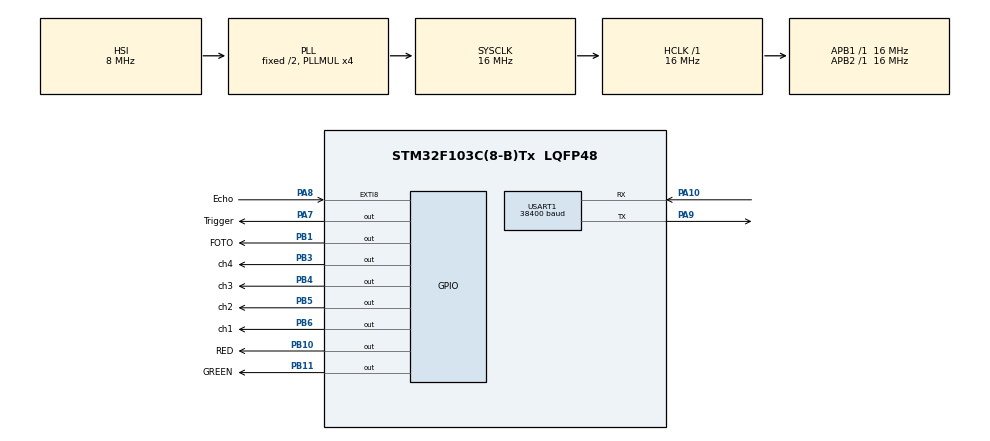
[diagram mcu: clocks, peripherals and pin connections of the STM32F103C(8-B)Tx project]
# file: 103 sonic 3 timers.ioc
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Mcu.Family=STM32F1
Mcu.Name=STM32F103C(8-B)Tx
Mcu.Package=LQFP48
NVIC.EXTI9_5_IRQn=true\:1\:0\:true\:false\:true\:true
NVIC.PriorityGroup=NVIC_PRIORITYGROUP_4
NVIC.TIM2_IRQn=true\:3\:0\:true\:false\:true\:true
NVIC.TIM3_IRQn=true\:2\:0\:true\:false\:true\:true
NVIC.TIM4_IRQn=true\:0\:0\:false\:false\:true\:true
PA10.Mode=Asynchronous
PA10.Signal=USART1_RX
PA13.Mode=Serial_Wire
PA13.Signal=SYS_JTMS-SWDIO
PA14.Mode=Serial_Wire
PA14.Signal=SYS_JTCK-SWCLK
PA7.GPIO_Label=Trigger
PA7.Signal=GPIO_Output
PA8.GPIO_Label=Echo
PA8.GPIO_ModeDefaultEXTI=GPIO_MODE_IT_RISING_FALLING
PA8.Signal=GPXTI8
PA9.Mode=Asynchronous
PA9.Signal=USART1_TX
PB1.GPIO_Label=FOTO
PB1.Signal=GPIO_Output
PB10.GPIO_Label=RED
PB10.Signal=GPIO_Output
PB11.GPIO_Label=GREEN
PB11.Signal=GPIO_Output
PB3.GPIO_Label=ch4
PB3.Signal=GPIO_Output
PB4.GPIO_Label=ch3
PB4.Signal=GPIO_Output
PB5.GPIO_Label=ch2
PB5.Signal=GPIO_Output
PB6.GPIO_Label=ch1
PB6.Signal=GPIO_Output
ProjectManager.HeapSize=0x200
ProjectManager.StackSize=0x400
ProjectManager.TargetToolchain=MDK-ARM V5
RCC.AHBFreq_Value=16000000
RCC.APB1Freq_Value=16000000
RCC.APB1TimFreq_Value=16000000
RCC.APB2Freq_Value=16000000
RCC.APB2TimFreq_Value=16000000
RCC.HCLKFreq_Value=16000000
RCC.PLLMUL=RCC_PLL_MUL4
RCC.SYSCLKFreq_VALUE=16000000
RCC.SYSCLKSource=RCC_SYSCLKSOURCE_PLLCLK
RCC.USBFreq_Value=16000000
TIM2.Period=100
TIM2.Prescaler=15999
TIM3.Period=65000
TIM3.Prescaler=15
TIM4.Period=24
TIM4.Prescaler=15
USART1.BaudRate=38400
USART1.VirtualMode=VM_ASYNC
VP_TIM2_VS_ClockSourceINT.Mode=Internal
VP_TIM3_VS_ClockSourceINT.Mode=Internal
VP_TIM4_VS_ClockSourceINT.Mode=Internal
board=custom

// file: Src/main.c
/**
  ******************************************************************************
  * @file           : main.c
  * @brief          : Main program body
  ******************************************************************************
  ** This notice applies to any and all portions of this file
  * that are not between comment pairs USER CODE BEGIN and
  * USER CODE END. Other portions of this file, whether
  * inserted by the user or by software development tools
  * are owned by their respective copyright owners.
  *
  * COPYRIGHT(c) 2018 STMicroelectronics
  *
  * Redistribution and use in source and binary forms, with or without modification,
  * are permitted provided that the following conditions are met:
  *   1. Redistributions of source code must retain the above copyright notice,
  *      this list of conditions and the following disclaimer.
  *   2. Redistributions in binary form must reproduce the above copyright notice,
  *      this list of conditions and the following disclaimer in the documentation
  *      and/or other materials provided with the distribution.
  *   3. Neither the name of STMicroelectronics nor the names of its contributors
  *      may be used to endorse or promote products derived from this software
  *      without specific prior written permission.
  *
  * THIS SOFTWARE IS PROVIDED BY THE COPYRIGHT HOLDERS AND CONTRIBUTORS "AS IS"
  * AND ANY EXPRESS OR IMPLIED WARRANTIES, INCLUDING, BUT NOT LIMITED TO, THE
  * IMPLIED WARRANTIES OF MERCHANTABILITY AND FITNESS FOR A PARTICULAR PURPOSE ARE
  * DISCLAIMED. IN NO EVENT SHALL THE COPYRIGHT HOLDER OR CONTRIBUTORS BE LIABLE
  * FOR ANY DIRECT, INDIRECT, INCIDENTAL, SPECIAL, EXEMPLARY, OR CONSEQUENTIAL
  * DAMAGES (INCLUDING, BUT NOT LIMITED TO, PROCUREMENT OF SUBSTITUTE GOODS OR
  * SERVICES; LOSS OF USE, DATA, OR PROFITS; OR BUSINESS INTERRUPTION) HOWEVER
  * CAUSED AND ON ANY THEORY OF LIABILITY, WHETHER IN CONTRACT, STRICT LIABILITY,
  * OR TORT (INCLUDING NEGLIGENCE OR OTHERWISE) ARISING IN ANY WAY OUT OF THE USE
  * OF THIS SOFTWARE, EVEN IF ADVISED OF THE POSSIBILITY OF SUCH DAMAGE.
  *
  ******************************************************************************
  */
#include "main.h"
#include "stm32f1xx_hal.h"

TIM_HandleTypeDef htim2;
TIM_HandleTypeDef htim3;
TIM_HandleTypeDef htim4;

UART_HandleTypeDef huart1;

/* USER CODE BEGIN PV */
/* Private variables ---------------------------------------------------------*/
volatile uint16_t duration=0, range=0, distance=0;
volatile uint8_t catcher=0, devider=57, state_set;
int set_range=350, gist=10;
int ms_start=0, ms_current=0, ms_interval=800;
/* USER CODE END PV */

void SystemClock_Config(void);
static void MX_GPIO_Init(void);
static void MX_USART1_UART_Init(void);
static void MX_TIM2_Init(void);
static void MX_TIM3_Init(void);
static void MX_TIM4_Init(void);

/* USER CODE BEGIN PFP */
/* Private function prototypes -----------------------------------------------*/

/* USER CODE END PFP */

/* USER CODE BEGIN 0 */
#ifdef __GNUC__
/* With GCC/RAISONANCE, small printf (option LD Linker->Libraries->Small printf
   set to 'Yes') calls __io_putchar() */
#define PUTCHAR_PROTOTYPE int __io_putchar(int ch)
#else
#define PUTCHAR_PROTOTYPE int fputc(int ch, FILE *f)
#endif /* __GNUC__ */

#define DIVIDER 57
/* USER CODE END 0 */

int main(void)
{

  /* MCU Configuration----------------------------------------------------------*/

  /* Reset of all peripherals, Initializes the Flash interface and the Systick. */
  HAL_Init();

  /* Configure the system clock */
  SystemClock_Config();

  /* Initialize all configured peripherals */
  MX_GPIO_Init();
  MX_USART1_UART_Init();
  MX_TIM2_Init();
  MX_TIM3_Init();
  MX_TIM4_Init();
  /* USER CODE BEGIN 2 */
	HAL_Delay(3000);
	HAL_TIM_Base_Start(&htim2);
	HAL_TIM_Base_Start_IT(&htim2);

  state_set |= HAL_GPIO_ReadPin(ch1_GPIO_Port,ch1_Pin);
   state_set |= HAL_GPIO_ReadPin(ch2_GPIO_Port,ch2_Pin)<<1;
  state_set |= HAL_GPIO_ReadPin(ch3_GPIO_Port,ch3_Pin)<<2;
  state_set |= HAL_GPIO_ReadPin(ch4_GPIO_Port,ch4_Pin)<<3;

  switch(state_set)
  {
	case 0xF: set_range=350; break;
    case 0xE: set_range=300; break;
    case 0xD: set_range=250; break;
    case 0xB: set_range=200; break;
	case 0x7: set_range=150; break;
    case 0x3: set_range=100; break;
    case 0x5: set_range=50; break;
    default: set_range=350;

  }

  /* USER CODE END 2 */

  /* Infinite loop */
  /* USER CODE BEGIN WHILE */
  while (1)
  {
		distance=duration/DIVIDER;
	  if((distance <(set_range-gist)) /*| ((duration/DIVIDER) >150)*/)
	  {
		  ms_start=HAL_GetTick();
		  HAL_GPIO_WritePin(GREEN_GPIO_Port,GREEN_Pin, GPIO_PIN_RESET);
			HAL_GPIO_WritePin(FOTO_GPIO_Port, FOTO_Pin, GPIO_PIN_RESET);
			HAL_GPIO_WritePin(GPIOB, GPIO_PIN_0, GPIO_PIN_SET);
      //add commit
	  }
	  if(distance >(set_range+gist) /* & ((duration/DIVIDER) <150)*/)
	  {

		  if(HAL_GetTick()-ms_start >= ms_interval)
		  {
			  ms_start=HAL_GetTick();
			  HAL_GPIO_WritePin(GREEN_GPIO_Port,GREEN_Pin, GPIO_PIN_SET);
				HAL_GPIO_WritePin(FOTO_GPIO_Port, FOTO_Pin, GPIO_PIN_SET);
				HAL_GPIO_WritePin(GPIOB, GPIO_PIN_0, GPIO_PIN_RESET);
		  }
	  }
	  //HAL_Delay(100);
  /* USER CODE END WHILE */

  }

}

void SystemClock_Config(void)
{

  RCC_OscInitTypeDef RCC_OscInitStruct;
  RCC_ClkInitTypeDef RCC_ClkInitStruct;

    /**Initializes the CPU, AHB and APB busses clocks
    */
  RCC_OscInitStruct.OscillatorType = RCC_OSCILLATORTYPE_HSI;
  RCC_OscInitStruct.HSIState = RCC_HSI_ON;
  RCC_OscInitStruct.HSICalibrationValue = 16;
  RCC_OscInitStruct.PLL.PLLState = RCC_PLL_ON;
  RCC_OscInitStruct.PLL.PLLSource = RCC_PLLSOURCE_HSI_DIV2;
  RCC_OscInitStruct.PLL.PLLMUL = RCC_PLL_MUL4;
  if (HAL_RCC_OscConfig(&RCC_OscInitStruct) != HAL_OK)
  {
    _Error_Handler(__FILE__, __LINE__);
  }

    /**Initializes the CPU, AHB and APB busses clocks
    */
  RCC_ClkInitStruct.ClockType = RCC_CLOCKTYPE_HCLK|RCC_CLOCKTYPE_SYSCLK
                              |RCC_CLOCKTYPE_PCLK1|RCC_CLOCKTYPE_PCLK2;
  RCC_ClkInitStruct.SYSCLKSource = RCC_SYSCLKSOURCE_PLLCLK;
  RCC_ClkInitStruct.AHBCLKDivider = RCC_SYSCLK_DIV1;
  RCC_ClkInitStruct.APB1CLKDivider = RCC_HCLK_DIV1;
  RCC_ClkInitStruct.APB2CLKDivider = RCC_HCLK_DIV1;

  if (HAL_RCC_ClockConfig(&RCC_ClkInitStruct, FLASH_LATENCY_0) != HAL_OK)
  {
    _Error_Handler(__FILE__, __LINE__);
  }

    /**Configure the Systick interrupt time
    */
  HAL_SYSTICK_Config(HAL_RCC_GetHCLKFreq()/1000);

    /**Configure the Systick
    */
  HAL_SYSTICK_CLKSourceConfig(SYSTICK_CLKSOURCE_HCLK);

  /* SysTick_IRQn interrupt configuration */
  HAL_NVIC_SetPriority(SysTick_IRQn, 0, 0);
}

/* TIM2 init function */
static void MX_TIM2_Init(void)
{

  TIM_ClockConfigTypeDef sClockSourceConfig;
  TIM_MasterConfigTypeDef sMasterConfig;

  htim2.Instance = TIM2;
  htim2.Init.Prescaler = 15999;
  htim2.Init.CounterMode = TIM_COUNTERMODE_UP;
  htim2.Init.Period = 69;
  htim2.Init.ClockDivision = TIM_CLOCKDIVISION_DIV1;
  htim2.Init.AutoReloadPreload = TIM_AUTORELOAD_PRELOAD_DISABLE;
  if (HAL_TIM_Base_Init(&htim2) != HAL_OK)
  {
    _Error_Handler(__FILE__, __LINE__);
  }

  sClockSourceConfig.ClockSource = TIM_CLOCKSOURCE_INTERNAL;
  if (HAL_TIM_ConfigClockSource(&htim2, &sClockSourceConfig) != HAL_OK)
  {
    _Error_Handler(__FILE__, __LINE__);
  }

  sMasterConfig.MasterOutputTrigger = TIM_TRGO_RESET;
  sMasterConfig.MasterSlaveMode = TIM_MASTERSLAVEMODE_DISABLE;
  if (HAL_TIMEx_MasterConfigSynchronization(&htim2, &sMasterConfig) != HAL_OK)
  {
    _Error_Handler(__FILE__, __LINE__);
  }

}

/* TIM3 init function */
static void MX_TIM3_Init(void)
{

  TIM_ClockConfigTypeDef sClockSourceConfig;
  TIM_MasterConfigTypeDef sMasterConfig;

  htim3.Instance = TIM3;
  htim3.Init.Prescaler = 15;
  htim3.Init.CounterMode = TIM_COUNTERMODE_UP;
  htim3.Init.Period = 65000;
  htim3.Init.ClockDivision = TIM_CLOCKDIVISION_DIV1;
  htim3.Init.AutoReloadPreload = TIM_AUTORELOAD_PRELOAD_DISABLE;
  if (HAL_TIM_Base_Init(&htim3) != HAL_OK)
  {
    _Error_Handler(__FILE__, __LINE__);
  }

  sClockSourceConfig.ClockSource = TIM_CLOCKSOURCE_INTERNAL;
  if (HAL_TIM_ConfigClockSource(&htim3, &sClockSourceConfig) != HAL_OK)
  {
    _Error_Handler(__FILE__, __LINE__);
  }

  sMasterConfig.MasterOutputTrigger = TIM_TRGO_RESET;
  sMasterConfig.MasterSlaveMode = TIM_MASTERSLAVEMODE_DISABLE;
  if (HAL_TIMEx_MasterConfigSynchronization(&htim3, &sMasterConfig) != HAL_OK)
  {
    _Error_Handler(__FILE__, __LINE__);
  }

}

/* TIM4 init function */
static void MX_TIM4_Init(void)
{

  TIM_ClockConfigTypeDef sClockSourceConfig;
  TIM_MasterConfigTypeDef sMasterConfig;

  htim4.Instance = TIM4;
  htim4.Init.Prescaler = 15;
  htim4.Init.CounterMode = TIM_COUNTERMODE_UP;
  htim4.Init.Period = 19;
  htim4.Init.ClockDivision = TIM_CLOCKDIVISION_DIV1;
  htim4.Init.AutoReloadPreload = TIM_AUTORELOAD_PRELOAD_DISABLE;
  if (HAL_TIM_Base_Init(&htim4) != HAL_OK)
  {
    _Error_Handler(__FILE__, __LINE__);
  }

  sClockSourceConfig.ClockSource = TIM_CLOCKSOURCE_INTERNAL;
  if (HAL_TIM_ConfigClockSource(&htim4, &sClockSourceConfig) != HAL_OK)
  {
    _Error_Handler(__FILE__, __LINE__);
  }

  sMasterConfig.MasterOutputTrigger = TIM_TRGO_RESET;
  sMasterConfig.MasterSlaveMode = TIM_MASTERSLAVEMODE_DISABLE;
  if (HAL_TIMEx_MasterConfigSynchronization(&htim4, &sMasterConfig) != HAL_OK)
  {
    _Error_Handler(__FILE__, __LINE__);
  }

}

/* USART1 init function */
static void MX_USART1_UART_Init(void)
{

  huart1.Instance = USART1;
  huart1.Init.BaudRate = 38400;
  huart1.Init.WordLength = UART_WORDLENGTH_8B;
  huart1.Init.StopBits = UART_STOPBITS_1;
  huart1.Init.Parity = UART_PARITY_NONE;
  huart1.Init.Mode = UART_MODE_TX_RX;
  huart1.Init.HwFlowCtl = UART_HWCONTROL_NONE;
  huart1.Init.OverSampling = UART_OVERSAMPLING_16;
  if (HAL_UART_Init(&huart1) != HAL_OK)
  {
    _Error_Handler(__FILE__, __LINE__);
  }

}

/** Configure pins as
        * Analog
        * Input
        * Output
        * EVENT_OUT
        * EXTI
*/
static void MX_GPIO_Init(void)
{

  GPIO_InitTypeDef GPIO_InitStruct;

  /* GPIO Ports Clock Enable */
  __HAL_RCC_GPIOA_CLK_ENABLE();
  __HAL_RCC_GPIOB_CLK_ENABLE();

  /*Configure GPIO pin Output Level */
  HAL_GPIO_WritePin(Trigger_GPIO_Port, Trigger_Pin, GPIO_PIN_RESET);

  /*Configure GPIO pin Output Level */
  HAL_GPIO_WritePin(GPIOB, FOTO_Pin|RED_Pin|GREEN_Pin|ch4_Pin
                          |ch3_Pin|ch2_Pin|ch1_Pin, GPIO_PIN_SET);

  /*Configure GPIO pin : Trigger_Pin */
  GPIO_InitStruct.Pin = Trigger_Pin;
  GPIO_InitStruct.Mode = GPIO_MODE_OUTPUT_PP;
  GPIO_InitStruct.Pull = GPIO_NOPULL;
  GPIO_InitStruct.Speed = GPIO_SPEED_FREQ_LOW;
  HAL_GPIO_Init(Trigger_GPIO_Port, &GPIO_InitStruct);

  /*Configure GPIO pins : FOTO_Pin RED_Pin GREEN_Pin ch4_Pin
                           ch3_Pin ch2_Pin ch1_Pin */
  GPIO_InitStruct.Pin = FOTO_Pin|RED_Pin|GREEN_Pin|ch4_Pin
                          |ch3_Pin|ch2_Pin|ch1_Pin|GPIO_PIN_0;
  GPIO_InitStruct.Mode = GPIO_MODE_OUTPUT_PP;
  GPIO_InitStruct.Pull = GPIO_PULLUP;
  GPIO_InitStruct.Speed = GPIO_SPEED_FREQ_LOW;
  HAL_GPIO_Init(GPIOB, &GPIO_InitStruct);

  /*Configure GPIO pin : Echo_Pin */
  GPIO_InitStruct.Pin = Echo_Pin;
  GPIO_InitStruct.Mode = GPIO_MODE_IT_RISING_FALLING;
  GPIO_InitStruct.Pull = GPIO_NOPULL;
  HAL_GPIO_Init(Echo_GPIO_Port, &GPIO_InitStruct);

  /* EXTI interrupt init*/
  HAL_NVIC_SetPriority(EXTI9_5_IRQn, 1, 0);
  HAL_NVIC_EnableIRQ(EXTI9_5_IRQn);

}

void _Error_Handler(char *file, int line)
{
  while(1)
  {
  }
}

/************************ (C) COPYRIGHT STMicroelectronics *****END OF FILE****/
